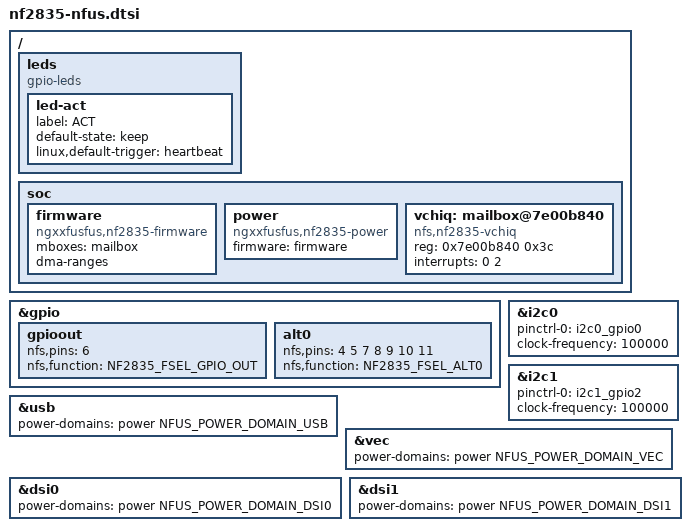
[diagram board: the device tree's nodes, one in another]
#include <dt-bindings/power/ngxxfusfus-power.h>

/ {
	leds {
		compatible = "gpio-leds";

		led-act {
			label = "ACT";
			default-state = "keep";
			linux,default-trigger = "heartbeat";
		};
	};

	soc {
		firmware: firmware {
			compatible = "ngxxfusfus,nf2835-firmware", "simple-mfd";
			#address-cells = <1>;
			#size-cells = <1>;

			mboxes = <&mailbox>;
			dma-ranges;
		};

		power: power {
			compatible = "ngxxfusfus,nf2835-power";
			firmware = <&firmware>;
			#power-domain-cells = <1>;
		};

		vchiq: mailbox@7e00b840 {
			compatible = "nfs,nf2835-vchiq";
			reg = <0x7e00b840 0x3c>;
			interrupts = <0 2>;
		};
	};
};

&gpio {
	pinctrl-names = "default";

	gpioout: gpioout {
		nfs,pins = <6>;
		nfs,function = <NF2835_FSEL_GPIO_OUT>;
	};

	alt0: alt0 {
		nfs,pins = <4 5 7 8 9 10 11>;
		nfs,function = <NF2835_FSEL_ALT0>;
	};
};

&i2c0 {
	pinctrl-names = "default";
	pinctrl-0 = <&i2c0_gpio0>;
	status = "okay";
	clock-frequency = <100000>;
};

&i2c1 {
	pinctrl-names = "default";
	pinctrl-0 = <&i2c1_gpio2>;
	status = "okay";
	clock-frequency = <100000>;
};

&usb {
	power-domains = <&power NFUS_POWER_DOMAIN_USB>;
};

&vec {
	power-domains = <&power NFUS_POWER_DOMAIN_VEC>;
	status = "okay";
};

&dsi0 {
	power-domains = <&power NFUS_POWER_DOMAIN_DSI0>;
};

&dsi1 {
	power-domains = <&power NFUS_POWER_DOMAIN_DSI1>;
};
